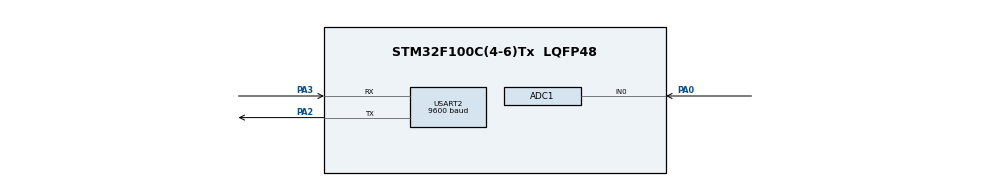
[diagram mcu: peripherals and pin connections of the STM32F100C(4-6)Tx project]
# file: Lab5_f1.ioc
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ADC1.Channel-0\#ChannelRegularConversion=ADC_CHANNEL_0
ADC1.ContinuousConvMode=ENABLE
ADC1.NbrOfConversionFlag=1
ADC1.Rank-0\#ChannelRegularConversion=1
ADC1.SamplingTime-0\#ChannelRegularConversion=ADC_SAMPLETIME_1CYCLE_5
ADC1.master=1
Mcu.Family=STM32F1
Mcu.Name=STM32F100C(4-6)Tx
Mcu.Package=LQFP48
NVIC.PriorityGroup=NVIC_PRIORITYGROUP_4
NVIC.TIM2_IRQn=true\:0\:0\:false\:false\:true\:true\:true\:true
NVIC.USART2_IRQn=true\:0\:0\:false\:false\:true\:true\:true\:true
PA0-WKUP.Signal=ADCx_IN0
PA2.Mode=Asynchronous
PA2.Signal=USART2_TX
PA3.Mode=Asynchronous
PA3.Signal=USART2_RX
ProjectManager.HeapSize=0x200
ProjectManager.StackSize=0x400
ProjectManager.TargetToolchain=STM32CubeIDE
RCC.APB1Freq_Value=8000000
RCC.APB2Freq_Value=8000000
SH.ADCx_IN0.0=ADC1_IN0,IN0
TIM2.Period=9
TIM2.Prescaler=7999
USART2.BaudRate=9600
USART2.VirtualMode=VM_ASYNC
VP_SYS_VS_ND.Mode=No_Debug
VP_TIM2_VS_ClockSourceINT.Mode=Internal
board=custom

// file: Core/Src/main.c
/* USER CODE BEGIN Header */
/**
  ******************************************************************************
  * @file           : main.c
  * @brief          : Main program body
  ******************************************************************************
  * @attention
  *
  * Copyright (c) 2024 STMicroelectronics.
  * All rights reserved.
  *
  * This software is licensed under terms that can be found in the LICENSE file
  * in the root directory of this software component.
  * If no LICENSE file comes with this software, it is provided AS-IS.
  *
  ******************************************************************************
  */
/* USER CODE END Header */
#include "main.h"
#include "adc.h"
#include "tim.h"
#include "usart.h"
#include "gpio.h"

/* USER CODE BEGIN Includes */
#include "software_timer.h"
#include "software_uart.h"

/* USER CODE END Includes */

void SystemClock_Config(void);

int main(void)
{

  /* MCU Configuration--------------------------------------------------------*/

  /* Reset of all peripherals, Initializes the Flash interface and the Systick. */
  HAL_Init();

  /* Configure the system clock */
  SystemClock_Config();

  /* Initialize all configured peripherals */
  MX_GPIO_Init();
  MX_TIM2_Init();
  MX_USART2_UART_Init();
  MX_ADC1_Init();
  /* USER CODE BEGIN 2 */
  //UART_SendString(&huart2, msg);
  HAL_ADC_Start(&hadc1);
  timer_init();
  setTimer(1, 1000);
  setTimer(2, 500);
  Init_Parser(&huart2, &hadc1);
  UART_StartReceive(&huart2);

  /* USER CODE END 2 */

  /* Infinite loop */
  while (1)
  {
	  //HAL_UART_Transmit(&huart2, string, 10, 500);
	  //HAL_Delay(1000);
    /* USER CODE BEGIN 3 */
	  if(buffer_flag){
	  		  command_parser_fsm();
	  		  buffer_flag = 0;
	  	  }
	  	  uart_communication_fsm();
  }
  /* USER CODE END 3 */
}

void SystemClock_Config(void)
{
  RCC_OscInitTypeDef RCC_OscInitStruct = {0};
  RCC_ClkInitTypeDef RCC_ClkInitStruct = {0};
  RCC_PeriphCLKInitTypeDef PeriphClkInit = {0};

  /** Initializes the RCC Oscillators according to the specified parameters
  * in the RCC_OscInitTypeDef structure.
  */
  RCC_OscInitStruct.OscillatorType = RCC_OSCILLATORTYPE_HSI;
  RCC_OscInitStruct.HSIState = RCC_HSI_ON;
  RCC_OscInitStruct.HSICalibrationValue = RCC_HSICALIBRATION_DEFAULT;
  RCC_OscInitStruct.PLL.PLLState = RCC_PLL_NONE;
  if (HAL_RCC_OscConfig(&RCC_OscInitStruct) != HAL_OK)
  {
    Error_Handler();
  }

  /** Initializes the CPU, AHB and APB buses clocks
  */
  RCC_ClkInitStruct.ClockType = RCC_CLOCKTYPE_HCLK|RCC_CLOCKTYPE_SYSCLK
                              |RCC_CLOCKTYPE_PCLK1|RCC_CLOCKTYPE_PCLK2;
  RCC_ClkInitStruct.SYSCLKSource = RCC_SYSCLKSOURCE_HSI;
  RCC_ClkInitStruct.AHBCLKDivider = RCC_SYSCLK_DIV1;
  RCC_ClkInitStruct.APB1CLKDivider = RCC_HCLK_DIV1;
  RCC_ClkInitStruct.APB2CLKDivider = RCC_HCLK_DIV1;

  if (HAL_RCC_ClockConfig(&RCC_ClkInitStruct, FLASH_LATENCY_0) != HAL_OK)
  {
    Error_Handler();
  }
  PeriphClkInit.PeriphClockSelection = RCC_PERIPHCLK_ADC;
  PeriphClkInit.AdcClockSelection = RCC_ADCPCLK2_DIV2;
  if (HAL_RCCEx_PeriphCLKConfig(&PeriphClkInit) != HAL_OK)
  {
    Error_Handler();
  }
}

void Error_Handler(void)
{
  __disable_irq();
  while (1)
  {
  }
}
